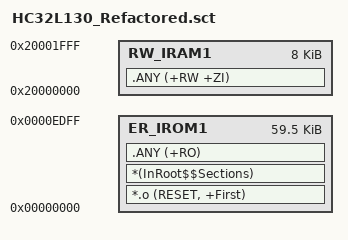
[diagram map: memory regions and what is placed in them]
; 0xEE00起保留身份区，所有可执行代码必须位于其前方。
LR_IROM1 0x00000000 0x0000EE00 {
  ER_IROM1 0x00000000 0x0000EE00 {
    *.o (RESET, +First)
    *(InRoot$$Sections)
    .ANY (+RO)
  }
  RW_IRAM1 0x20000000 0x00002000 {
    .ANY (+RW +ZI)
  }
}
